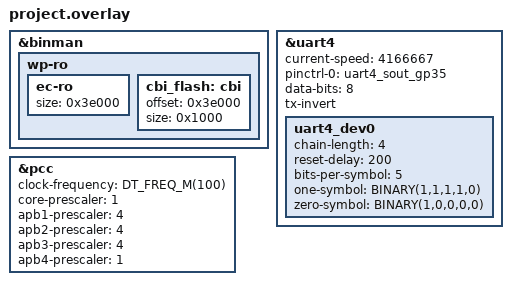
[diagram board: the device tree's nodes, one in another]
/* Copyright 2026 The ChromiumOS Authors
 * Use of this source code is governed by a BSD-style license that can be
 * found in the LICENSE file.
 */

/* mensa program common DTS includes */

#include <cros/integrated_fwid.dtsi>
#include <dt-bindings/macros.h>

#include "../psl.dtsi"
#include "../adc.dtsi"
#include "../common.dtsi"
#include "battery.dtsi"
#include <mensa/overlay.dtsi>

/* mensa project DTS includes */

#include <cros/cbi_flash.dtsi>
#include "gpios.dtsi"
#include "i2c.dtsi"
#include "interrupts.dtsi"
#include "keyboard.dtsi"
#include "led_pins.dtsi"
#include "led_policy.dtsi"
#include "fan.dtsi"
#include "temp_sensors.dtsi"

/* mensa overrides follow... */

&binman {
	wp-ro {
		ec-ro {
			size = <0x3e000>;
		};
		cbi_flash: cbi {
			/*
			 * CBI section size is 0x1000 bytes, the
			 * CBI portion lies at the end of EC_RO section.
			 */
			offset = <0x3e000>;
			size = <0x1000>;
		};
	};
};

&uart4 {
	status = "okay";
	current-speed = <4166667>;
	pinctrl-0 = <&uart4_sout_gp35>;
	pinctrl-names = "default";
	data-bits = <8>;
	tx-invert;

	uart4_dev0: uart4_dev0 {
		status = "okay";
		chain-length = <4>;
		reset-delay = <200>;
		bits-per-symbol = <5>;
		one-symbol = <BINARY(1,1,1,1,0)>;
		zero-symbol = <BINARY(1,0,0,0,0)>;
	};
};

&pcc {
	clock-frequency = <DT_FREQ_M(100)>;
	core-prescaler = <1>;
	apb1-prescaler = <4>;
	apb2-prescaler = <4>;
	apb3-prescaler = <4>;
	apb4-prescaler = <1>;
};
